AUTOSAR XML (schema 4-0-3)
package /ComponentTypes
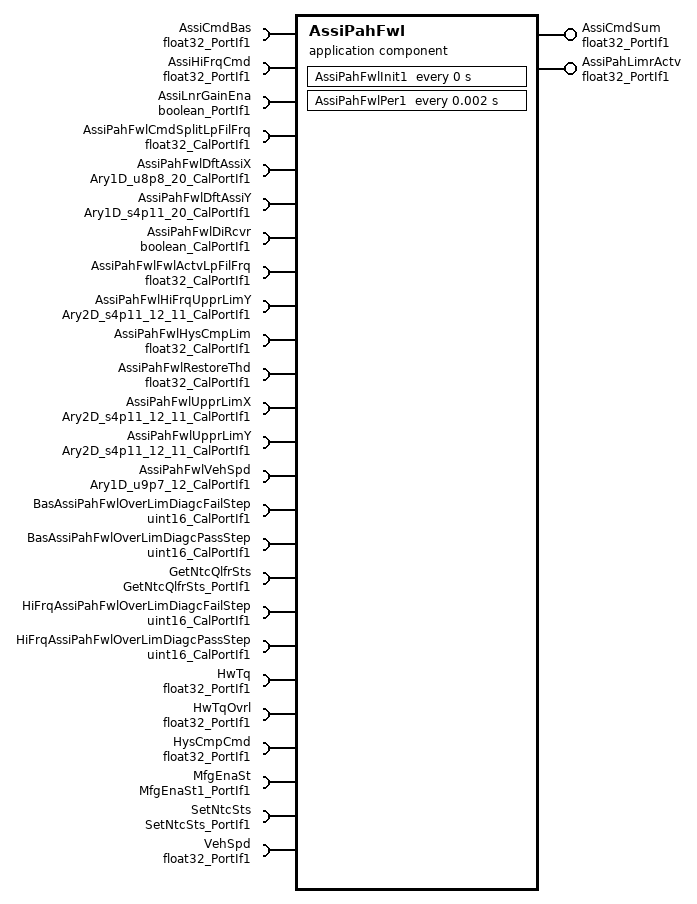
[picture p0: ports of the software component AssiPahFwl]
  application sw component type AssiPahFwl
    provide port AssiCmdSum: nonqueued-sender-com-spec{data-element=Val, init-value=0}, provided-interface=float32_PortIf1
    provide port AssiPahLimrActv: nonqueued-sender-com-spec{data-element=Val, init-value=0}, provided-interface=float32_PortIf1
    25 x require port:
      AssiCmdBas: nonqueued-receiver-com-spec{data-element=Val, filter=data-filter-type=ALWAYS, init-value=0}, required-interface=float32_PortIf1
      AssiHiFrqCmd: nonqueued-receiver-com-spec{data-element=Val, filter=data-filter-type=ALWAYS, init-value=0}, required-interface=float32_PortIf1
      AssiLnrGainEna: nonqueued-receiver-com-spec{data-element=Logl, filter=data-filter-type=ALWAYS, init-value=0}, required-interface=boolean_PortIf1
      AssiPahFwlCmdSplitLpFilFrq: parameter-require-com-spec{init-value=50, parameter=Val}, required-interface=float32_CalPortIf1
      AssiPahFwlDftAssiX: parameter-require-com-spec{init-value=[0, 410, 460, 476, 503, 527, 558, 585, 619, 649, 677, 710, 738, 769, 797, 824, 1024, 1224, 1920, 2560], parameter=Ary1D}, required-interface=Ary1D_u8p8_20_CalPortIf1
      AssiPahFwlDftAssiY: parameter-require-com-spec{init-value=[0, 0, 0, 0, 6, 20, 43, 66, 96, 127, 156, 193, 229, 274, 319, 365, 786, 1358, 3635, 5120], parameter=Ary1D}, required-interface=Ary1D_s4p11_20_CalPortIf1
      AssiPahFwlDiRcvr: parameter-require-com-spec{init-value=0, parameter=Logl}, required-interface=boolean_CalPortIf1
      AssiPahFwlFwlActvLpFilFrq: parameter-require-com-spec{init-value=0.1, parameter=Val}, required-interface=float32_CalPortIf1
      AssiPahFwlHiFrqUpprLimY: parameter-require-com-spec{init-value=12 x 11 x 18022, parameter=Ary2D}, required-interface=Ary2D_s4p11_12_11_CalPortIf1
      AssiPahFwlHysCmpLim: parameter-require-com-spec{init-value=0.15, parameter=Val}, required-interface=float32_CalPortIf1
      AssiPahFwlRestoreThd: parameter-require-com-spec{init-value=0.01, parameter=Val}, required-interface=float32_CalPortIf1
      AssiPahFwlUpprLimX: parameter-require-com-spec{init-value=[[-20480, -15360, -6144, -4096, -2048, 0, 2048, 4096, 6144, 15360, 20480], [-20480, -15360, -6144, -4096, -2048, 0, 2048, 4096, 6144, 15360, 20480], [-20480, -15360, -6144, -4096, -2048, 0, 2048, 4096, 6144, 15360, 20480], [-20480, -15360, -6144, -4096, -2048, 0, 2048, 4096, 6144, 15360, 20480], [-20480, -15360, -6144, -4096, -614, 0, 2048, 4096, 6144, 15360, 20480], [-20480, -15360, -6144, -4096, -614, 0, 2048, 4096, 6144, 15360, 20480], [-20480, -15360, -6144, -4096, -369, 0, 2048, 4096, 6144, 15360, 20480], [-20480, -15360, -6144, -4096, -369, 0, 2048, 4096, 6144, 15360, 20480], [-20480, -15360, -6144, -4096, -369, 0, 2048, 4096, 6144, 15360, 20480], [-20480, -15360, -6144, -4096, -369, 0, 2048, 4096, 6144, 15360, 20480], [-20480, -15360, -6144, -4096, -369, 0, 2048, 4096, 6144, 15360, 20480], [-20480, -15360, -6144, -4096, -369, 0, 2048, 4096, 6144, 15360, 20480]], parameter=Ary2D}, required-interface=Ary2D_s4p11_12_11_CalPortIf1
      AssiPahFwlUpprLimY: parameter-require-com-spec{init-value=12 x 11 x 18022, parameter=Ary2D}, required-interface=Ary2D_s4p11_12_11_CalPortIf1
      AssiPahFwlVehSpd: parameter-require-com-spec{init-value=[0, 256, 1280, 3200, 6400, 9600, 12800, 19200, 25600, 31872, 32000, 32128], parameter=Ary1D}, required-interface=Ary1D_u9p7_12_CalPortIf1
      BasAssiPahFwlOverLimDiagcFailStep: parameter-require-com-spec{init-value=1311, parameter=Val}, required-interface=uint16_CalPortIf1
      BasAssiPahFwlOverLimDiagcPassStep: parameter-require-com-spec{init-value=1311, parameter=Val}, required-interface=uint16_CalPortIf1
      GetNtcQlfrSts: required-interface=GetNtcQlfrSts_PortIf1
      HiFrqAssiPahFwlOverLimDiagcFailStep: parameter-require-com-spec{init-value=1311, parameter=Val}, required-interface=uint16_CalPortIf1
      HiFrqAssiPahFwlOverLimDiagcPassStep: parameter-require-com-spec{init-value=1311, parameter=Val}, required-interface=uint16_CalPortIf1
      HwTq: nonqueued-receiver-com-spec{data-element=Val, filter=data-filter-type=ALWAYS, init-value=0}, required-interface=float32_PortIf1
      HwTqOvrl: nonqueued-receiver-com-spec{data-element=Val, filter=data-filter-type=ALWAYS, init-value=0}, required-interface=float32_PortIf1
      HysCmpCmd: nonqueued-receiver-com-spec{data-element=Val, filter=data-filter-type=ALWAYS, init-value=0}, required-interface=float32_PortIf1
      MfgEnaSt: nonqueued-receiver-com-spec{data-element=Val, filter=data-filter-type=ALWAYS, init-value=0}, required-interface=MfgEnaSt1_PortIf1
      SetNtcSts: required-interface=SetNtcSts_PortIf1
      VehSpd: nonqueued-receiver-com-spec{data-element=Val, filter=data-filter-type=ALWAYS, init-value=0}, required-interface=float32_PortIf1
    behavior AssiPahFwl_InternalBehavior
      ar-typed-per-instance-memorys:
        18 x data, all with sw-calibration-access=READ-ONLY:
          AssiPrfmncPrev: type=boolean
          CombdAssiPrev: type=float32
          dAssiPahFwlActvRaw: type=float32
          dAssiPahFwlBasAssiCmdOverLim: type=boolean
          dAssiPahFwlBasAssiLimd: type=float32
          dAssiPahFwlBasAssiLowrLim: type=float32
          dAssiPahFwlBasAssiUpprLim: type=float32
          dAssiPahFwlHiFrqAssiLowrLimFild: type=float32
          dAssiPahFwlHiFrqAssiUpprLimFild: type=float32
          dAssiPahFwlHiFrqCmdHpPah: type=float32
          dAssiPahFwlHiFrqCmdLpPah: type=float32
          dAssiPahFwlHiFrqCmdOverLim: type=boolean
          dAssiPahFwlHiFrqLpLimd: type=float32
          dAssiPahFwlSumInp: type=float32
          FwlActvLpFilStVari: type=FilLpRec1
          HiFrqCmdLpFilStVari: type=FilLpRec1
          LowrLimLpFilStVari: type=FilLpRec1
          UpprLimLpFilStVari: type=FilLpRec1
      timing event AssiPahFwl_InitEvent: start-on-event=AssiPahFwlInit1, period=0
      timing event TMT_AssiPahFwlPer1: start-on-event=AssiPahFwlPer1, period=0.002
      runnable AssiPahFwlInit1
        sync call SC_SetNtcSts_Oper: operation=SetNtcSts.Oper, timeout=0
      runnable AssiPahFwlPer1
        data-receive-point-by-arguments:
          8 x access:
            REC_AssiCmdBas_Val: accessed-variable=AssiCmdBas.Val
            REC_AssiHiFrqCmd_Val: accessed-variable=AssiHiFrqCmd.Val
            REC_AssiLnrGainEna_Logl: accessed-variable=AssiLnrGainEna.Logl
            REC_HwTq_Val: accessed-variable=HwTq.Val
            REC_HwTqOvrl_Val: accessed-variable=HwTqOvrl.Val
            REC_HysCmpCmd_Val: accessed-variable=HysCmpCmd.Val
            REC_MfgEnaSt_Val: accessed-variable=MfgEnaSt.Val
            REC_VehSpd_Val: accessed-variable=VehSpd.Val
        data-send-points:
          access SEND_AssiCmdSum_Val: accessed-variable=AssiCmdSum.Val
          access SEND_AssiPahLimrActv_Val: accessed-variable=AssiPahLimrActv.Val
        sync call SC_GetNtcQlfrSts_Oper: operation=GetNtcQlfrSts.Oper, timeout=0
        sync call SC_SetNtcSts_Oper: operation=SetNtcSts.Oper, timeout=0
  swc implementation AssiPahFwl_Implementation: behavior=AssiPahFwl_InternalBehavior
    code-descriptors:
      code Default: artifact-descriptors=autosar-engineering-object={short-label=Default, category=SWSRC}
